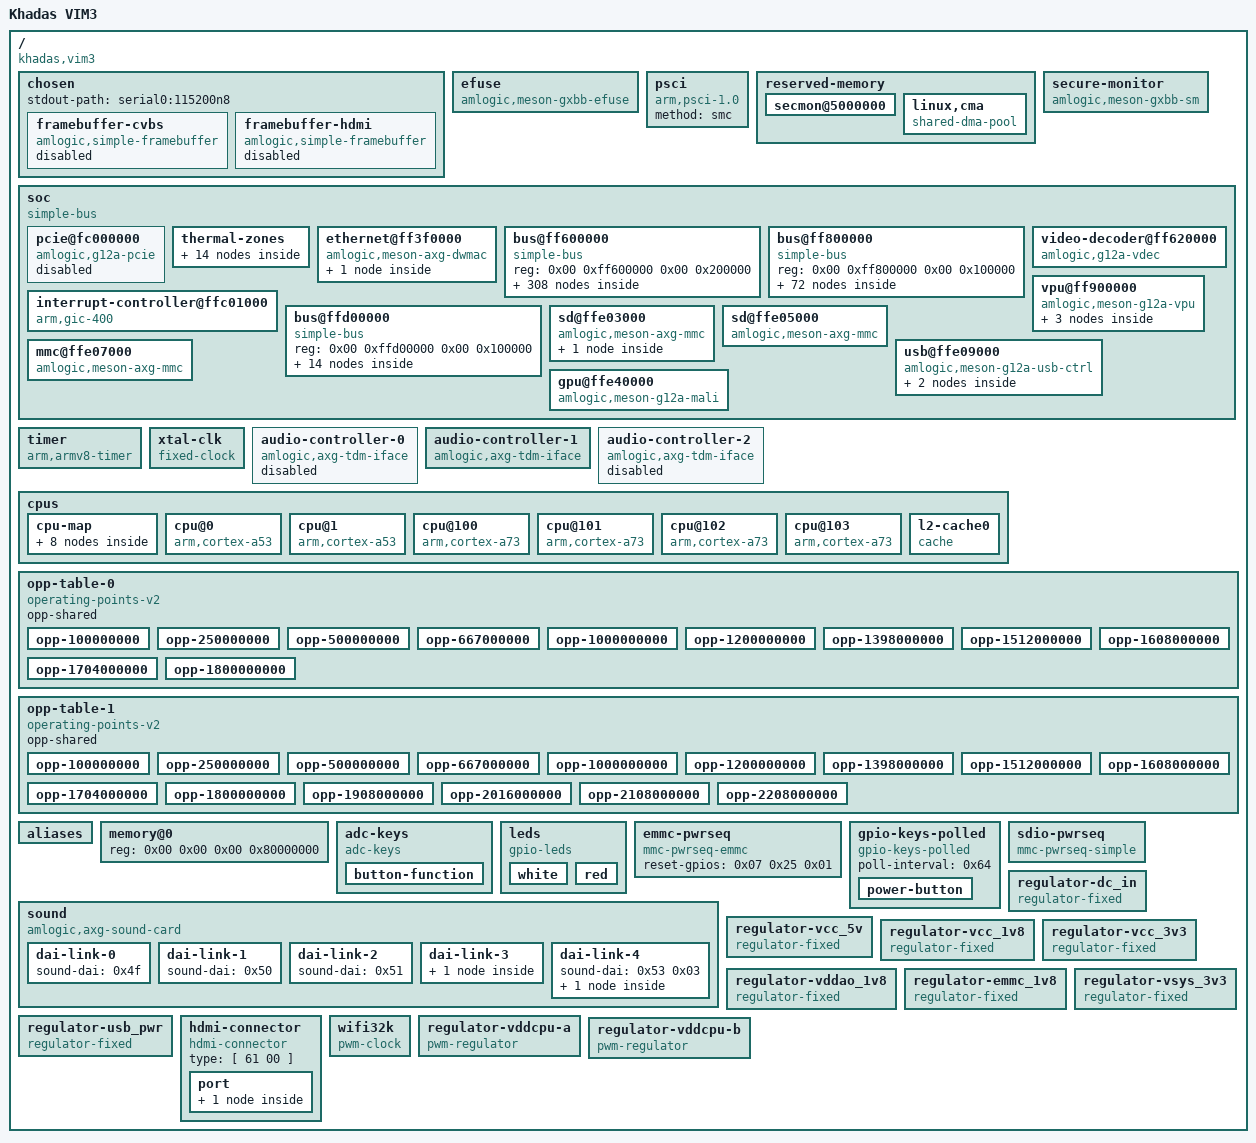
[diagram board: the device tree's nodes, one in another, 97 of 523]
/dts-v1/;

/ {
	interrupt-parent = < 0x01 >;
	#address-cells = < 0x02 >;
	#size-cells = < 0x02 >;
	compatible = "khadas,vim3\0amlogic,a311d\0amlogic,g12b";
	model = "Khadas VIM3";

	chosen {
		#address-cells = < 0x02 >;
		#size-cells = < 0x02 >;
		ranges;
		stdout-path = "serial0:115200n8";

		framebuffer-cvbs {
			compatible = "amlogic,simple-framebuffer\0simple-framebuffer";
			amlogic,pipeline = "vpu-cvbs";
			clocks = < 0x02 0xa8 0x02 0x35 0x02 0x3a >;
			status = "disabled";
			power-domains = < 0x03 0x00 >;
		};

		framebuffer-hdmi {
			compatible = "amlogic,simple-framebuffer\0simple-framebuffer";
			amlogic,pipeline = "vpu-hdmi";
			clocks = < 0x02 0xa8 0x02 0x35 0x02 0x3a >;
			status = "disabled";
			power-domains = < 0x03 0x00 >;
		};
	};

	efuse {
		compatible = "amlogic,meson-gxbb-efuse";
		clocks = < 0x02 0x6a >;
		#address-cells = < 0x01 >;
		#size-cells = < 0x01 >;
		read-only;
		secure-monitor = < 0x04 >;
	};

	psci {
		compatible = "arm,psci-1.0";
		method = "smc";
	};

	reserved-memory {
		#address-cells = < 0x02 >;
		#size-cells = < 0x02 >;
		ranges;

		secmon@5000000 {
			reg = < 0x00 0x5000000 0x00 0x300000 >;
			no-map;
		};

		linux,cma {
			compatible = "shared-dma-pool";
			reusable;
			size = < 0x00 0x10000000 >;
			alignment = < 0x00 0x400000 >;
			linux,cma-default;
		};
	};

	secure-monitor {
		compatible = "amlogic,meson-gxbb-sm";
		phandle = < 0x04 >;
	};

	soc {
		compatible = "simple-bus";
		#address-cells = < 0x02 >;
		#size-cells = < 0x02 >;
		ranges;

		pcie@fc000000 {
			compatible = "amlogic,g12a-pcie\0snps,dw-pcie";
			reg = < 0x00 0xfc000000 0x00 0x400000 0x00 0xff648000 0x00 0x2000 0x00 0xfc400000 0x00 0x200000 >;
			reg-names = "elbi\0cfg\0config";
			interrupts = < 0x00 0xdd 0x04 >;
			#interrupt-cells = < 0x01 >;
			interrupt-map-mask = < 0x00 0x00 0x00 0x00 >;
			interrupt-map = < 0x00 0x00 0x00 0x00 0x01 0x00 0xdf 0x04 >;
			bus-range = < 0x00 0xff >;
			#address-cells = < 0x03 >;
			#size-cells = < 0x02 >;
			device_type = "pci";
			ranges = < 0x81000000 0x00 0x00 0x00 0xfc600000 0x00 0x100000 0x82000000 0x00 0xfc700000 0x00 0xfc700000 0x00 0x1900000 >;
			clocks = < 0x02 0x30 0x02 0x2d 0x02 0xc9 >;
			clock-names = "general\0pclk\0port";
			resets = < 0x05 0x0c 0x05 0x0f >;
			reset-names = "port\0apb";
			num-lanes = < 0x01 >;
			phys = < 0x06 0x02 >;
			phy-names = "pcie";
			status = "disabled";
			reset-gpios = < 0x07 0x39 0x01 >;
		};

		thermal-zones {

			cpu-thermal {
				polling-delay = < 0x3e8 >;
				polling-delay-passive = < 0x64 >;
				thermal-sensors = < 0x08 >;

				trips {

					cpu-passive {
						temperature = < 0x14c08 >;
						hysteresis = < 0x7d0 >;
						type = "passive";
						phandle = < 0x09 >;
					};

					cpu-hot {
						temperature = < 0x17318 >;
						hysteresis = < 0x7d0 >;
						type = "hot";
						phandle = < 0x10 >;
					};

					cpu-critical {
						temperature = < 0x1adb0 >;
						hysteresis = < 0x7d0 >;
						type = "critical";
					};
				};

				cooling-maps {

					map0 {
						trip = < 0x09 >;
						cooling-device = < 0x0a 0xffffffff 0xffffffff 0x0b 0xffffffff 0xffffffff 0x0c 0xffffffff 0xffffffff 0x0d 0xffffffff 0xffffffff 0x0e 0xffffffff 0xffffffff 0x0f 0xffffffff 0xffffffff >;
					};

					map1 {
						trip = < 0x10 >;
						cooling-device = < 0x0a 0xffffffff 0xffffffff 0x0b 0xffffffff 0xffffffff 0x0c 0xffffffff 0xffffffff 0x0d 0xffffffff 0xffffffff 0x0e 0xffffffff 0xffffffff 0x0f 0xffffffff 0xffffffff >;
					};
				};
			};

			ddr-thermal {
				polling-delay = < 0x3e8 >;
				polling-delay-passive = < 0x64 >;
				thermal-sensors = < 0x11 >;

				trips {

					ddr-passive {
						temperature = < 0x14c08 >;
						hysteresis = < 0x7d0 >;
						type = "passive";
						phandle = < 0x12 >;
					};

					ddr-critical {
						temperature = < 0x1adb0 >;
						hysteresis = < 0x7d0 >;
						type = "critical";
					};
				};

				cooling-maps {

					map {
						trip = < 0x12 >;
						cooling-device = < 0x13 0xffffffff 0xffffffff >;
					};
				};
			};
		};

		ethernet@ff3f0000 {
			compatible = "amlogic,meson-axg-dwmac\0snps,dwmac-3.70a\0snps,dwmac";
			reg = < 0x00 0xff3f0000 0x00 0x10000 0x00 0xff634540 0x00 0x08 >;
			interrupts = < 0x00 0x08 0x04 >;
			interrupt-names = "macirq";
			clocks = < 0x02 0x26 0x02 0x02 0x02 0x0d >;
			clock-names = "stmmaceth\0clkin0\0clkin1";
			rx-fifo-depth = < 0x1000 >;
			tx-fifo-depth = < 0x800 >;
			status = "okay";
			power-domains = < 0x03 0x01 >;
			pinctrl-0 = < 0x14 0x15 >;
			pinctrl-names = "default";
			phy-mode = "rgmii";
			phy-handle = < 0x16 >;
			amlogic,tx-delay-ns = < 0x02 >;

			mdio {
				#address-cells = < 0x01 >;
				#size-cells = < 0x00 >;
				compatible = "snps,dwmac-mdio";
				phandle = < 0x22 >;
			};
		};

		bus@ff600000 {
			compatible = "simple-bus";
			reg = < 0x00 0xff600000 0x00 0x200000 >;
			#address-cells = < 0x02 >;
			#size-cells = < 0x02 >;
			ranges = < 0x00 0x00 0x00 0xff600000 0x00 0x200000 >;

			hdmi-tx@0 {
				compatible = "amlogic,meson-g12a-dw-hdmi";
				reg = < 0x00 0x00 0x00 0x10000 >;
				interrupts = < 0x00 0x39 0x01 >;
				resets = < 0x05 0x13 0x05 0x42 0x05 0x4f >;
				reset-names = "hdmitx_apb\0hdmitx\0hdmitx_phy";
				clocks = < 0x02 0xa8 0x02 0x35 0x02 0x3a >;
				clock-names = "isfr\0iahb\0venci";
				#address-cells = < 0x01 >;
				#size-cells = < 0x00 >;
				#sound-dai-cells = < 0x00 >;
				status = "okay";
				pinctrl-0 = < 0x17 0x18 >;
				pinctrl-names = "default";
				hdmi-supply = < 0x19 >;
				phandle = < 0x29 >;

				port@0 {
					reg = < 0x00 >;

					endpoint {
						remote-endpoint = < 0x1a >;
						phandle = < 0x33 >;
					};
				};

				port@1 {
					reg = < 0x01 >;

					endpoint {
						remote-endpoint = < 0x1b >;
						phandle = < 0x54 >;
					};
				};
			};

			bus@30000 {
				compatible = "simple-bus";
				reg = < 0x00 0x30000 0x00 0x2000 >;
				#address-cells = < 0x02 >;
				#size-cells = < 0x02 >;
				ranges = < 0x00 0x00 0x00 0x30000 0x00 0x2000 >;

				rng@218 {
					compatible = "amlogic,meson-rng";
					reg = < 0x00 0x218 0x00 0x04 >;
				};
			};

			audio-controller@32000 {
				compatible = "amlogic,t9015";
				reg = < 0x00 0x32000 0x00 0x14 >;
				#sound-dai-cells = < 0x00 >;
				sound-name-prefix = "ACODEC";
				clocks = < 0x02 0x24 >;
				clock-names = "pclk";
				resets = < 0x05 0x3d >;
				status = "disabled";
			};

			bus@34400 {
				compatible = "simple-bus";
				reg = < 0x00 0x34400 0x00 0x400 >;
				#address-cells = < 0x02 >;
				#size-cells = < 0x02 >;
				ranges = < 0x00 0x00 0x00 0x34400 0x00 0x400 >;

				pinctrl@40 {
					compatible = "amlogic,meson-g12a-periphs-pinctrl";
					#address-cells = < 0x02 >;
					#size-cells = < 0x02 >;
					ranges;
					phandle = < 0x1c >;

					bank@40 {
						reg = < 0x00 0x40 0x00 0x4c 0x00 0xe8 0x00 0x18 0x00 0x120 0x00 0x18 0x00 0x2c0 0x00 0x40 0x00 0x340 0x00 0x1c >;
						reg-names = "gpio\0pull\0pull-enable\0mux\0ds";
						gpio-controller;
						#gpio-cells = < 0x02 >;
						gpio-ranges = < 0x1c 0x00 0x00 0x56 >;
						phandle = < 0x07 >;
					};

					cec_ao_a_h {
						phandle = < 0x28 >;

						mux {
							groups = "cec_ao_a_h";
							function = "cec_ao_a_h";
							bias-disable;
						};
					};

					cec_ao_b_h {
						phandle = < 0x2a >;

						mux {
							groups = "cec_ao_b_h";
							function = "cec_ao_b_h";
							bias-disable;
						};
					};

					emmc {
						phandle = < 0x3f >;

						mux-0 {
							groups = "emmc_nand_d0\0emmc_nand_d1\0emmc_nand_d2\0emmc_nand_d3\0emmc_nand_d4\0emmc_nand_d5\0emmc_nand_d6\0emmc_nand_d7\0emmc_cmd";
							function = "emmc";
							bias-pull-up;
							drive-strength-microamp = < 0xfa0 >;
						};

						mux-1 {
							groups = "emmc_clk";
							function = "emmc";
							bias-disable;
							drive-strength-microamp = < 0xfa0 >;
						};
					};

					emmc-ds {
						phandle = < 0x40 >;

						mux {
							groups = "emmc_nand_ds";
							function = "emmc";
							bias-pull-down;
							drive-strength-microamp = < 0xfa0 >;
						};
					};

					emmc_clk_gate {
						phandle = < 0x41 >;

						mux {
							groups = "BOOT_8";
							function = "gpio_periphs";
							bias-pull-down;
							drive-strength-microamp = < 0xfa0 >;
						};
					};

					hdmitx_ddc {
						phandle = < 0x18 >;

						mux {
							groups = "hdmitx_sda\0hdmitx_sck";
							function = "hdmitx";
							bias-disable;
							drive-strength-microamp = < 0xfa0 >;
						};
					};

					hdmitx_hpd {
						phandle = < 0x17 >;

						mux {
							groups = "hdmitx_hpd_in";
							function = "hdmitx";
							bias-disable;
						};
					};

					i2c0-sda-c {

						mux {
							groups = "i2c0_sda_c";
							function = "i2c0";
							bias-disable;
							drive-strength-microamp = < 0xbb8 >;
						};
					};

					i2c0-sck-c {

						mux {
							groups = "i2c0_sck_c";
							function = "i2c0";
							bias-disable;
							drive-strength-microamp = < 0xbb8 >;
						};
					};

					i2c0-sda-z0 {

						mux {
							groups = "i2c0_sda_z0";
							function = "i2c0";
							bias-disable;
							drive-strength-microamp = < 0xbb8 >;
						};
					};

					i2c0-sck-z1 {

						mux {
							groups = "i2c0_sck_z1";
							function = "i2c0";
							bias-disable;
							drive-strength-microamp = < 0xbb8 >;
						};
					};

					i2c0-sda-z7 {

						mux {
							groups = "i2c0_sda_z7";
							function = "i2c0";
							bias-disable;
							drive-strength-microamp = < 0xbb8 >;
						};
					};

					i2c0-sda-z8 {

						mux {
							groups = "i2c0_sda_z8";
							function = "i2c0";
							bias-disable;
							drive-strength-microamp = < 0xbb8 >;
						};
					};

					i2c1-sda-x {

						mux {
							groups = "i2c1_sda_x";
							function = "i2c1";
							bias-disable;
							drive-strength-microamp = < 0xbb8 >;
						};
					};

					i2c1-sck-x {

						mux {
							groups = "i2c1_sck_x";
							function = "i2c1";
							bias-disable;
							drive-strength-microamp = < 0xbb8 >;
						};
					};

					i2c1-sda-h2 {

						mux {
							groups = "i2c1_sda_h2";
							function = "i2c1";
							bias-disable;
							drive-strength-microamp = < 0xbb8 >;
						};
					};

					i2c1-sck-h3 {

						mux {
							groups = "i2c1_sck_h3";
							function = "i2c1";
							bias-disable;
							drive-strength-microamp = < 0xbb8 >;
						};
					};

					i2c1-sda-h6 {

						mux {
							groups = "i2c1_sda_h6";
							function = "i2c1";
							bias-disable;
							drive-strength-microamp = < 0xbb8 >;
						};
					};

					i2c1-sck-h7 {

						mux {
							groups = "i2c1_sck_h7";
							function = "i2c1";
							bias-disable;
							drive-strength-microamp = < 0xbb8 >;
						};
					};

					i2c2-sda-x {

						mux {
							groups = "i2c2_sda_x";
							function = "i2c2";
							bias-disable;
							drive-strength-microamp = < 0xbb8 >;
						};
					};

					i2c2-sck-x {

						mux {
							groups = "i2c2_sck_x";
							function = "i2c2";
							bias-disable;
							drive-strength-microamp = < 0xbb8 >;
						};
					};

					i2c2-sda-z {

						mux {
							groups = "i2c2_sda_z";
							function = "i2c2";
							bias-disable;
							drive-strength-microamp = < 0xbb8 >;
						};
					};

					i2c2-sck-z {

						mux {
							groups = "i2c2_sck_z";
							function = "i2c2";
							bias-disable;
							drive-strength-microamp = < 0xbb8 >;
						};
					};

					i2c3-sda-h {

						mux {
							groups = "i2c3_sda_h";
							function = "i2c3";
							bias-disable;
							drive-strength-microamp = < 0xbb8 >;
						};
					};

					i2c3-sck-h {

						mux {
							groups = "i2c3_sck_h";
							function = "i2c3";
							bias-disable;
							drive-strength-microamp = < 0xbb8 >;
						};
					};

					i2c3-sda-a {

						mux {
							groups = "i2c3_sda_a";
							function = "i2c3";
							bias-disable;
							drive-strength-microamp = < 0xbb8 >;
						};
					};

					i2c3-sck-a {

						mux {
							groups = "i2c3_sck_a";
							function = "i2c3";
							bias-disable;
							drive-strength-microamp = < 0xbb8 >;
						};
					};

					mclk0-a {

						mux {
							groups = "mclk0_a";
							function = "mclk0";
							bias-disable;
							drive-strength-microamp = < 0xbb8 >;
						};
					};

					mclk1-a {

						mux {
							groups = "mclk1_a";
							function = "mclk1";
							bias-disable;
							drive-strength-microamp = < 0xbb8 >;
						};
					};

					mclk1-x {

						mux {
							groups = "mclk1_x";
							function = "mclk1";
							bias-disable;
							drive-strength-microamp = < 0xbb8 >;
						};
					};

					mclk1-z {

						mux {
							groups = "mclk1_z";
							function = "mclk1";
							bias-disable;
							drive-strength-microamp = < 0xbb8 >;
						};
					};

					pdm-din0-a {

						mux {
							groups = "pdm_din0_a";
							function = "pdm";
							bias-disable;
						};
					};

					pdm-din0-c {

						mux {
							groups = "pdm_din0_c";
							function = "pdm";
							bias-disable;
						};
					};

					pdm-din0-x {

						mux {
							groups = "pdm_din0_x";
							function = "pdm";
							bias-disable;
						};
					};

					pdm-din0-z {

						mux {
							groups = "pdm_din0_z";
							function = "pdm";
							bias-disable;
						};
					};

					pdm-din1-a {

						mux {
							groups = "pdm_din1_a";
							function = "pdm";
							bias-disable;
						};
					};

					pdm-din1-c {

						mux {
							groups = "pdm_din1_c";
							function = "pdm";
							bias-disable;
						};
					};

					pdm-din1-x {

						mux {
							groups = "pdm_din1_x";
							function = "pdm";
							bias-disable;
						};
					};

					pdm-din1-z {

						mux {
							groups = "pdm_din1_z";
							function = "pdm";
							bias-disable;
						};
					};

					pdm-din2-a {

						mux {
							groups = "pdm_din2_a";
							function = "pdm";
							bias-disable;
						};
					};

					pdm-din2-c {

						mux {
							groups = "pdm_din2_c";
							function = "pdm";
							bias-disable;
						};
					};

					pdm-din2-x {

						mux {
							groups = "pdm_din2_x";
							function = "pdm";
							bias-disable;
						};
					};

					pdm-din2-z {

						mux {
							groups = "pdm_din2_z";
							function = "pdm";
							bias-disable;
						};
					};

					pdm-din3-a {

						mux {
							groups = "pdm_din3_a";
							function = "pdm";
							bias-disable;
						};
					};

					pdm-din3-c {

						mux {
							groups = "pdm_din3_c";
							function = "pdm";
							bias-disable;
						};
					};

					pdm-din3-x {

						mux {
							groups = "pdm_din3_x";
							function = "pdm";
							bias-disable;
						};
					};

					pdm-din3-z {

						mux {
							groups = "pdm_din3_z";
							function = "pdm";
							bias-disable;
						};
					};

					pdm-dclk-a {

						mux {
							groups = "pdm_dclk_a";
							function = "pdm";
							bias-disable;
							drive-strength-microamp = < 0x1f4 >;
						};
					};

					pdm-dclk-c {

						mux {
							groups = "pdm_dclk_c";
							function = "pdm";
							bias-disable;
							drive-strength-microamp = < 0x1f4 >;
						};
					};

					pdm-dclk-x {

						mux {
							groups = "pdm_dclk_x";
							function = "pdm";
							bias-disable;
							drive-strength-microamp = < 0x1f4 >;
						};
					};

					pdm-dclk-z {

						mux {
							groups = "pdm_dclk_z";
							function = "pdm";
							bias-disable;
							drive-strength-microamp = < 0x1f4 >;
						};
					};

					pwm-a {

						mux {
							groups = "pwm_a";
							function = "pwm_a";
							bias-disable;
						};
					};

					pwm-b-x7 {

						mux {
							groups = "pwm_b_x7";
							function = "pwm_b";
							bias-disable;
						};
					};

					pwm-b-x19 {

						mux {
							groups = "pwm_b_x19";
							function = "pwm_b";
							bias-disable;
						};
					};

					pwm-c-c {

						mux {
							groups = "pwm_c_c";
							function = "pwm_c";
							bias-disable;
						};
					};

					pwm-c-x5 {

						mux {
							groups = "pwm_c_x5";
							function = "pwm_c";
							bias-disable;
						};
					};

					pwm-c-x8 {

						mux {
							groups = "pwm_c_x8";
							function = "pwm_c";
							bias-disable;
						};
					};

					pwm-d-x3 {

						mux {
							groups = "pwm_d_x3";
							function = "pwm_d";
							bias-disable;
						};
					};

					pwm-d-x6 {

						mux {
							groups = "pwm_d_x6";
							function = "pwm_d";
							bias-disable;
						};
					};

					pwm-e {
						phandle = < 0x34 >;

						mux {
							groups = "pwm_e";
							function = "pwm_e";
							bias-disable;
						};
					};

					pwm-f-x {

						mux {
							groups = "pwm_f_x";
							function = "pwm_f";
							bias-disable;
						};
					};

					pwm-f-h {

						mux {
							groups = "pwm_f_h";
							function = "pwm_f";
							bias-disable;
						};
					};

					sdcard_c {
						phandle = < 0x3d >;

						mux-0 {
							groups = "sdcard_d0_c\0sdcard_d1_c\0sdcard_d2_c\0sdcard_d3_c\0sdcard_cmd_c";
							function = "sdcard";
							bias-pull-up;
							drive-strength-microamp = < 0xfa0 >;
						};

						mux-1 {
							groups = "sdcard_clk_c";
							function = "sdcard";
							bias-disable;
							drive-strength-microamp = < 0xfa0 >;
						};
					};

					sdcard_clk_gate_c {
						phandle = < 0x3e >;

						mux {
							groups = "GPIOC_4";
							function = "gpio_periphs";
							bias-pull-down;
							drive-strength-microamp = < 0xfa0 >;
						};
					};

					sdcard_z {

						mux-0 {
							groups = "sdcard_d0_z\0sdcard_d1_z\0sdcard_d2_z\0sdcard_d3_z\0sdcard_cmd_z";
							function = "sdcard";
							bias-pull-up;
							drive-strength-microamp = < 0xfa0 >;
						};

						mux-1 {
							groups = "sdcard_clk_z";
							function = "sdcard";
							bias-disable;
							drive-strength-microamp = < 0xfa0 >;
						};
					};

					sdcard_clk_gate_z {

						mux {
							groups = "GPIOZ_6";
							function = "gpio_periphs";
							bias-pull-down;
							drive-strength-microamp = < 0xfa0 >;
						};
					};

					sdio {
						phandle = < 0x39 >;

						mux {
							groups = "sdio_d0\0sdio_d1\0sdio_d2\0sdio_d3\0sdio_clk\0sdio_cmd";
							function = "sdio";
							bias-disable;
							drive-strength-microamp = < 0xfa0 >;
						};
					};

					sdio_clk_gate {
						phandle = < 0x3a >;

						mux {
							groups = "GPIOX_4";
							function = "gpio_periphs";
							bias-pull-down;
							drive-strength-microamp = < 0xfa0 >;
						};
					};

					spdif-in-a10 {

						mux {
							groups = "spdif_in_a10";
							function = "spdif_in";
							bias-disable;
						};
					};

					spdif-in-a12 {

						mux {
							groups = "spdif_in_a12";
							function = "spdif_in";
							bias-disable;
						};
					};

					spdif-in-h {

						mux {
							groups = "spdif_in_h";
							function = "spdif_in";
							bias-disable;
						};
					};

					spdif-out-h {

						mux {
							groups = "spdif_out_h";
							function = "spdif_out";
							drive-strength-microamp = < 0x1f4 >;
							bias-disable;
						};
					};

					spdif-out-a11 {

						mux {
							groups = "spdif_out_a11";
							function = "spdif_out";
							drive-strength-microamp = < 0x1f4 >;
							bias-disable;
						};
					};

					spdif-out-a13 {

						mux {
							groups = "spdif_out_a13";
							function = "spdif_out";
							drive-strength-microamp = < 0x1f4 >;
							bias-disable;
						};
					};

					tdm-a-din0 {

						mux {
							groups = "tdm_a_din0";
							function = "tdm_a";
							bias-disable;
						};
					};

					tdm-a-din1 {

						mux {
							groups = "tdm_a_din1";
							function = "tdm_a";
							bias-disable;
						};
					};

					tdm-a-dout0 {

						mux {
							groups = "tdm_a_dout0";
							function = "tdm_a";
							bias-disable;
							drive-strength-microamp = < 0xbb8 >;
						};
					};

					tdm-a-dout1 {

						mux {
							groups = "tdm_a_dout1";
							function = "tdm_a";
							bias-disable;
							drive-strength-microamp = < 0xbb8 >;
						};
					};

					tdm-a-fs {

						mux {
							groups = "tdm_a_fs";
							function = "tdm_a";
							bias-disable;
							drive-strength-microamp = < 0xbb8 >;
						};
					};

					tdm-a-sclk {

						mux {
							groups = "tdm_a_sclk";
							function = "tdm_a";
							bias-disable;
							drive-strength-microamp = < 0xbb8 >;
						};
					};

					tdm-a-slv-fs {

						mux {
							groups = "tdm_a_slv_fs";
							function = "tdm_a";
							bias-disable;
						};
					};

					tdm-a-slv-sclk {

						mux {
							groups = "tdm_a_slv_sclk";
							function = "tdm_a";
							bias-disable;
						};
					};

					tdm-b-din0 {

						mux {
							groups = "tdm_b_din0";
							function = "tdm_b";
							bias-disable;
						};
					};

					tdm-b-din1 {

						mux {
							groups = "tdm_b_din1";
							function = "tdm_b";
							bias-disable;
						};
					};

					tdm-b-din2 {

						mux {
							groups = "tdm_b_din2";
							function = "tdm_b";
							bias-disable;
						};
					};

					tdm-b-din3-a {

						mux {
							groups = "tdm_b_din3_a";
							function = "tdm_b";
							bias-disable;
						};
					};

					tdm-b-din3-h {

						mux {
							groups = "tdm_b_din3_h";
							function = "tdm_b";
							bias-disable;
						};
					};

					tdm-b-dout0 {

						mux {
							groups = "tdm_b_dout0";
							function = "tdm_b";
							bias-disable;
							drive-strength-microamp = < 0xbb8 >;
						};
					};

					tdm-b-dout1 {

						mux {
							groups = "tdm_b_dout1";
							function = "tdm_b";
							bias-disable;
							drive-strength-microamp = < 0xbb8 >;
						};
					};

					tdm-b-dout2 {

						mux {
							groups = "tdm_b_dout2";
							function = "tdm_b";
							bias-disable;
							drive-strength-microamp = < 0xbb8 >;
						};
					};

					tdm-b-dout3-a {

						mux {
							groups = "tdm_b_dout3_a";
							function = "tdm_b";
							bias-disable;
							drive-strength-microamp = < 0xbb8 >;
						};
					};

					tdm-b-dout3-h {

						mux {
							groups = "tdm_b_dout3_h";
							function = "tdm_b";
							bias-disable;
							drive-strength-microamp = < 0xbb8 >;
						};
					};

					tdm-b-fs {

						mux {
							groups = "tdm_b_fs";
							function = "tdm_b";
							bias-disable;
							drive-strength-microamp = < 0xbb8 >;
						};
					};

					tdm-b-sclk {

						mux {
							groups = "tdm_b_sclk";
							function = "tdm_b";
							bias-disable;
							drive-strength-microamp = < 0xbb8 >;
						};
					};

					tdm-b-slv-fs {

						mux {
							groups = "tdm_b_slv_fs";
							function = "tdm_b";
							bias-disable;
						};
					};

					tdm-b-slv-sclk {

						mux {
							groups = "tdm_b_slv_sclk";
							function = "tdm_b";
							bias-disable;
						};
					};

					tdm-c-din0-a {

						mux {
							groups = "tdm_c_din0_a";
							function = "tdm_c";
							bias-disable;
						};
					};

					tdm-c-din0-z {

						mux {
							groups = "tdm_c_din0_z";
							function = "tdm_c";
							bias-disable;
						};
					};

					tdm-c-din1-a {

						mux {
							groups = "tdm_c_din1_a";
							function = "tdm_c";
							bias-disable;
						};
					};

					tdm-c-din1-z {

						mux {
							groups = "tdm_c_din1_z";
							function = "tdm_c";
							bias-disable;
						};
					};

					tdm-c-din2-a {

						mux {
							groups = "tdm_c_din2_a";
							function = "tdm_c";
							bias-disable;
						};
					};

					eth-leds {

						mux {
							groups = "eth_link_led\0eth_act_led";
							function = "eth";
							bias-disable;
						};
					};

					eth {
						phandle = < 0x14 >;

						mux {
							groups = "eth_mdio\0eth_mdc\0eth_rgmii_rx_clk\0eth_rx_dv\0eth_rxd0\0eth_rxd1\0eth_txen\0eth_txd0\0eth_txd1";
							function = "eth";
							drive-strength-microamp = < 0xfa0 >;
							bias-disable;
						};
					};

					eth-rgmii {
						phandle = < 0x15 >;

						mux {
							groups = "eth_rxd2_rgmii\0eth_rxd3_rgmii\0eth_rgmii_tx_clk\0eth_txd2_rgmii\0eth_txd3_rgmii";
							function = "eth";
							drive-strength-microamp = < 0xfa0 >;
							bias-disable;
						};
					};

					tdm-c-din2-z {

						mux {
							groups = "tdm_c_din2_z";
							function = "tdm_c";
							bias-disable;
						};
					};

					tdm-c-din3-a {

						mux {
							groups = "tdm_c_din3_a";
							function = "tdm_c";
							bias-disable;
						};
					};

					tdm-c-din3-z {

						mux {
							groups = "tdm_c_din3_z";
							function = "tdm_c";
							bias-disable;
						};
					};

					tdm-c-dout0-a {

						mux {
							groups = "tdm_c_dout0_a";
							function = "tdm_c";
							bias-disable;
							drive-strength-microamp = < 0xbb8 >;
						};
					};

					tdm-c-dout0-z {

						mux {
							groups = "tdm_c_dout0_z";
							function = "tdm_c";
							bias-disable;
							drive-strength-microamp = < 0xbb8 >;
						};
					};

					tdm-c-dout1-a {

						mux {
							groups = "tdm_c_dout1_a";
							function = "tdm_c";
							bias-disable;
							drive-strength-microamp = < 0xbb8 >;
						};
					};

					tdm-c-dout1-z {

						mux {
							groups = "tdm_c_dout1_z";
							function = "tdm_c";
							bias-disable;
							drive-strength-microamp = < 0xbb8 >;
						};
					};

					tdm-c-dout2-a {

						mux {
							groups = "tdm_c_dout2_a";
							function = "tdm_c";
							bias-disable;
							drive-strength-microamp = < 0xbb8 >;
						};
					};

					tdm-c-dout2-z {

						mux {
							groups = "tdm_c_dout2_z";
							function = "tdm_c";
							bias-disable;
							drive-strength-microamp = < 0xbb8 >;
						};
					};

					tdm-c-dout3-a {

						mux {
							groups = "tdm_c_dout3_a";
							function = "tdm_c";
							bias-disable;
							drive-strength-microamp = < 0xbb8 >;
						};
					};

					tdm-c-dout3-z {

						mux {
							groups = "tdm_c_dout3_z";
							function = "tdm_c";
							bias-disable;
							drive-strength-microamp = < 0xbb8 >;
						};
					};

					tdm-c-fs-a {

						mux {
							groups = "tdm_c_fs_a";
							function = "tdm_c";
							bias-disable;
							drive-strength-microamp = < 0xbb8 >;
						};
					};

					tdm-c-fs-z {

						mux {
							groups = "tdm_c_fs_z";
							function = "tdm_c";
							bias-disable;
							drive-strength-microamp = < 0xbb8 >;
						};
					};

					tdm-c-sclk-a {

						mux {
							groups = "tdm_c_sclk_a";
							function = "tdm_c";
							bias-disable;
							drive-strength-microamp = < 0xbb8 >;
						};
					};

					tdm-c-sclk-z {

						mux {
							groups = "tdm_c_sclk_z";
							function = "tdm_c";
							bias-disable;
							drive-strength-microamp = < 0xbb8 >;
						};
					};

					tdm-c-slv-fs-a {

						mux {
							groups = "tdm_c_slv_fs_a";
							function = "tdm_c";
							bias-disable;
						};
					};

					tdm-c-slv-fs-z {

						mux {
							groups = "tdm_c_slv_fs_z";
							function = "tdm_c";
							bias-disable;
						};
					};

					tdm-c-slv-sclk-a {

						mux {
							groups = "tdm_c_slv_sclk_a";
							function = "tdm_c";
							bias-disable;
						};
					};

					tdm-c-slv-sclk-z {

						mux {
							groups = "tdm_c_slv_sclk_z";
							function = "tdm_c";
							bias-disable;
						};
					};

					uart-a {
						phandle = < 0x36 >;

						mux {
							groups = "uart_a_tx\0uart_a_rx";
							function = "uart_a";
							bias-disable;
						};
					};

					uart-a-cts-rts {
						phandle = < 0x37 >;

						mux {
							groups = "uart_a_cts\0uart_a_rts";
							function = "uart_a";
							bias-disable;
						};
					};

					uart-b {

						mux {
							groups = "uart_b_tx\0uart_b_rx";
							function = "uart_b";
							bias-disable;
						};
					};

					uart-c {

						mux {
							groups = "uart_c_tx\0uart_c_rx";
							function = "uart_c";
							bias-disable;
						};
					};

					uart-c-cts-rts {

						mux {
							groups = "uart_c_cts\0uart_c_rts";
							function = "uart_c";
							bias-disable;
						};
					};
				};
			};

			temperature-sensor@34800 {
				compatible = "amlogic,g12a-cpu-thermal\0amlogic,g12a-thermal";
				reg = < 0x00 0x34800 0x00 0x50 >;
				interrupts = < 0x00 0x23 0x01 >;
				clocks = < 0x02 0xd4 >;
				#thermal-sensor-cells = < 0x00 >;
				amlogic,ao-secure = < 0x1d >;
				phandle = < 0x08 >;
			};

			temperature-sensor@34c00 {
				compatible = "amlogic,g12a-ddr-thermal\0amlogic,g12a-thermal";
				reg = < 0x00 0x34c00 0x00 0x50 >;
				interrupts = < 0x00 0x24 0x01 >;
				clocks = < 0x02 0xd4 >;
				#thermal-sensor-cells = < 0x00 >;
				amlogic,ao-secure = < 0x1d >;
				phandle = < 0x11 >;
			};

			phy@36000 {
				compatible = "amlogic,g12a-usb2-phy";
				reg = < 0x00 0x36000 0x00 0x2000 >;
				clocks = < 0x1e >;
				clock-names = "xtal";
				resets = < 0x05 0x30 >;
				reset-names = "phy";
				#phy-cells = < 0x00 >;
				phy-supply = < 0x1f >;
				phandle = < 0x44 >;
			};

			bus@38000 {
				compatible = "simple-bus";
				reg = < 0x00 0x38000 0x00 0x400 >;
				#address-cells = < 0x02 >;
				#size-cells = < 0x02 >;
				ranges = < 0x00 0x00 0x00 0x38000 0x00 0x400 >;

				video-lut@48 {
					compatible = "amlogic,canvas";
					reg = < 0x00 0x48 0x00 0x14 >;
					phandle = < 0x32 >;
				};
			};

			phy@3a000 {
				compatible = "amlogic,g12a-usb2-phy";
				reg = < 0x00 0x3a000 0x00 0x2000 >;
				clocks = < 0x1e >;
				clock-names = "xtal";
				resets = < 0x05 0x31 >;
				reset-names = "phy";
				#phy-cells = < 0x00 >;
				phy-supply = < 0x20 >;
				phandle = < 0x45 >;
			};

			bus@3c000 {
				compatible = "simple-bus";
				reg = < 0x00 0x3c000 0x00 0x1400 >;
				#address-cells = < 0x02 >;
				#size-cells = < 0x02 >;
				ranges = < 0x00 0x00 0x00 0x3c000 0x00 0x1400 >;

				system-controller@0 {
					compatible = "amlogic,meson-gx-hhi-sysctrl\0simple-mfd\0syscon";
					reg = < 0x00 0x00 0x00 0x400 >;

					clock-controller {
						compatible = "amlogic,g12b-clkc";
						#clock-cells = < 0x01 >;
						clocks = < 0x1e >;
						clock-names = "xtal";
						phandle = < 0x02 >;
					};

					power-controller {
						compatible = "amlogic,meson-g12a-pwrc";
						#power-domain-cells = < 0x01 >;
						amlogic,ao-sysctrl = < 0x21 >;
						resets = < 0x05 0x05 0x05 0x0a 0x05 0x0d 0x05 0x25 0x05 0x85 0x05 0x86 0x05 0x87 0x05 0x89 0x05 0x8c 0x05 0x8d 0x05 0xe7 >;
						reset-names = "viu\0venc\0vcbus\0bt656\0rdma\0venci\0vencp\0vdac\0vdi6\0vencl\0vid_lock";
						clocks = < 0x02 0x74 0x02 0x7c >;
						clock-names = "vpu\0vapb";
						assigned-clocks = < 0x02 0x6e 0x02 0x70 0x02 0x74 0x02 0x75 0x02 0x77 0x02 0x7b >;
						assigned-clock-parents = < 0x02 0x03 0x00 0x02 0x70 0x02 0x04 0x00 0x02 0x77 >;
						assigned-clock-rates = < 0x00 0x27bc86aa 0x00 0x00 0xee6b280 0x00 >;
						phandle = < 0x03 >;
					};
				};
			};

			phy@46000 {
				compatible = "amlogic,g12a-usb3-pcie-phy";
				reg = < 0x00 0x46000 0x00 0x2000 >;
				clocks = < 0x02 0xc9 >;
				clock-names = "ref_clk";
				resets = < 0x05 0x0e >;
				reset-names = "phy";
				assigned-clocks = < 0x02 0xc9 >;
				assigned-clock-rates = < 0x5f5e100 >;
				#phy-cells = < 0x01 >;
				phy-supply = < 0x20 >;
				phandle = < 0x06 >;
			};

			mdio-multiplexer@4c000 {
				compatible = "amlogic,g12a-mdio-mux";
				reg = < 0x00 0x4c000 0x00 0xa4 >;
				clocks = < 0x02 0x13 0x1e 0x02 0xb1 >;
				clock-names = "pclk\0clkin0\0clkin1";
				mdio-parent-bus = < 0x22 >;
				#address-cells = < 0x01 >;
				#size-cells = < 0x00 >;

				mdio@0 {
					reg = < 0x00 >;
					#address-cells = < 0x01 >;
					#size-cells = < 0x00 >;

					ethernet-phy@0 {
						reg = < 0x00 >;
						max-speed = < 0x3e8 >;
						interrupt-parent = < 0x23 >;
						interrupts = < 0x1a 0x08 >;
						phandle = < 0x16 >;
					};
				};

				mdio@1 {
					reg = < 0x01 >;
					#address-cells = < 0x01 >;
					#size-cells = < 0x00 >;

					ethernet_phy@8 {
						compatible = "ethernet-phy-id0180.3301\0ethernet-phy-ieee802.3-c22";
						interrupts = < 0x00 0x09 0x04 >;
						reg = < 0x08 >;
						max-speed = < 0x64 >;
					};
				};
			};

			audio-controller@40000 {
				compatible = "amlogic,g12a-pdm\0amlogic,axg-pdm";
				reg = < 0x00 0x40000 0x00 0x34 >;
				#sound-dai-cells = < 0x00 >;
				sound-name-prefix = "PDM";
				clocks = < 0x24 0x1e 0x24 0x39 0x24 0x3a >;
				clock-names = "pclk\0dclk\0sysclk";
				status = "disabled";
			};

			bus@42000 {
				compatible = "simple-bus";
				reg = < 0x00 0x42000 0x00 0x2000 >;
				#address-cells = < 0x02 >;
				#size-cells = < 0x02 >;
				ranges = < 0x00 0x00 0x00 0x42000 0x00 0x2000 >;

				clock-controller@0 {
					status = "okay";
					compatible = "amlogic,g12a-audio-clkc";
					reg = < 0x00 0x00 0x00 0xb4 >;
					#clock-cells = < 0x01 >;
					#reset-cells = < 0x01 >;
					clocks = < 0x02 0x25 0x02 0x0b 0x02 0x0c 0x02 0x0d 0x02 0x0e 0x02 0x4a 0x02 0x03 0x02 0x04 0x02 0x07 >;
					clock-names = "pclk\0mst_in0\0mst_in1\0mst_in2\0mst_in3\0mst_in4\0mst_in5\0mst_in6\0mst_in7";
					resets = < 0x05 0x41 >;
					phandle = < 0x24 >;
				};

				audio-controller@100 {
					compatible = "amlogic,g12a-toddr\0amlogic,axg-toddr";
					reg = < 0x00 0x100 0x00 0x2c >;
					#sound-dai-cells = < 0x00 >;
					sound-name-prefix = "TODDR_A";
					interrupts = < 0x00 0x94 0x01 >;
					clocks = < 0x24 0x29 >;
					resets = < 0x25 0x00 0x24 0x06 >;
					reset-names = "arb\0rst";
					status = "disabled";
				};

				audio-controller@140 {
					compatible = "amlogic,g12a-toddr\0amlogic,axg-toddr";
					reg = < 0x00 0x140 0x00 0x2c >;
					#sound-dai-cells = < 0x00 >;
					sound-name-prefix = "TODDR_B";
					interrupts = < 0x00 0x95 0x01 >;
					clocks = < 0x24 0x2a >;
					resets = < 0x25 0x01 0x24 0x07 >;
					reset-names = "arb\0rst";
					status = "disabled";
				};

				audio-controller@180 {
					compatible = "amlogic,g12a-toddr\0amlogic,axg-toddr";
					reg = < 0x00 0x180 0x00 0x2c >;
					#sound-dai-cells = < 0x00 >;
					sound-name-prefix = "TODDR_C";
					interrupts = < 0x00 0x96 0x01 >;
					clocks = < 0x24 0x2b >;
					resets = < 0x25 0x02 0x24 0x08 >;
					reset-names = "arb\0rst";
					status = "disabled";
				};

				audio-controller@1c0 {
					compatible = "amlogic,g12a-frddr\0amlogic,axg-frddr";
					reg = < 0x00 0x1c0 0x00 0x2c >;
					#sound-dai-cells = < 0x00 >;
					sound-name-prefix = "FRDDR_A";
					interrupts = < 0x00 0x98 0x01 >;
					clocks = < 0x24 0x26 >;
					resets = < 0x25 0x03 0x24 0x09 >;
					reset-names = "arb\0rst";
					status = "okay";
					phandle = < 0x4f >;
				};

				audio-controller@200 {
					compatible = "amlogic,g12a-frddr\0amlogic,axg-frddr";
					reg = < 0x00 0x200 0x00 0x2c >;
					#sound-dai-cells = < 0x00 >;
					sound-name-prefix = "FRDDR_B";
					interrupts = < 0x00 0x99 0x01 >;
					clocks = < 0x24 0x27 >;
					resets = < 0x25 0x04 0x24 0x0a >;
					reset-names = "arb\0rst";
					status = "okay";
					phandle = < 0x50 >;
				};

				audio-controller@240 {
					compatible = "amlogic,g12a-frddr\0amlogic,axg-frddr";
					reg = < 0x00 0x240 0x00 0x2c >;
					#sound-dai-cells = < 0x00 >;
					sound-name-prefix = "FRDDR_C";
					interrupts = < 0x00 0x9a 0x01 >;
					clocks = < 0x24 0x28 >;
					resets = < 0x25 0x05 0x24 0x0b >;
					reset-names = "arb\0rst";
					status = "okay";
					phandle = < 0x51 >;
				};

				reset-controller@280 {
					status = "okay";
					compatible = "amlogic,meson-axg-audio-arb";
					reg = < 0x00 0x280 0x00 0x04 >;
					#reset-cells = < 0x01 >;
					clocks = < 0x24 0x1d >;
					phandle = < 0x25 >;
				};

				audio-controller@300 {
					compatible = "amlogic,g12a-tdmin\0amlogic,axg-tdmin";
					reg = < 0x00 0x300 0x00 0x40 >;
					sound-name-prefix = "TDMIN_A";
					resets = < 0x24 0x01 >;
					clocks = < 0x24 0x1f 0x24 0x7b 0x24 0x74 0x24 0x82 0x24 0x82 >;
					clock-names = "pclk\0sclk\0sclk_sel\0lrclk\0lrclk_sel";
					status = "disabled";
				};

				audio-controller@340 {
					compatible = "amlogic,g12a-tdmin\0amlogic,axg-tdmin";
					reg = < 0x00 0x340 0x00 0x40 >;
					sound-name-prefix = "TDMIN_B";
					resets = < 0x24 0x02 >;
					clocks = < 0x24 0x20 0x24 0x7c 0x24 0x75 0x24 0x83 0x24 0x83 >;
					clock-names = "pclk\0sclk\0sclk_sel\0lrclk\0lrclk_sel";
					status = "disabled";
				};

				audio-controller@380 {
					compatible = "amlogic,g12a-tdmin\0amlogic,axg-tdmin";
					reg = < 0x00 0x380 0x00 0x40 >;
					sound-name-prefix = "TDMIN_C";
					resets = < 0x24 0x03 >;
					clocks = < 0x24 0x21 0x24 0x7d 0x24 0x76 0x24 0x84 0x24 0x84 >;
					clock-names = "pclk\0sclk\0sclk_sel\0lrclk\0lrclk_sel";
					status = "disabled";
				};

				audio-controller@3c0 {
					compatible = "amlogic,g12a-tdmin\0amlogic,axg-tdmin";
					reg = < 0x00 0x3c0 0x00 0x40 >;
					sound-name-prefix = "TDMIN_LB";
					resets = < 0x24 0x04 >;
					clocks = < 0x24 0x22 0x24 0x7e 0x24 0x77 0x24 0x85 0x24 0x85 >;
					clock-names = "pclk\0sclk\0sclk_sel\0lrclk\0lrclk_sel";
					status = "disabled";
				};

				audio-controller@400 {
					compatible = "amlogic,g12a-spdifin\0amlogic,axg-spdifin";
					reg = < 0x00 0x400 0x00 0x30 >;
					#sound-dai-cells = < 0x00 >;
					sound-name-prefix = "SPDIFIN";
					interrupts = < 0x00 0x97 0x01 >;
					clocks = < 0x24 0x2d 0x24 0x38 >;
					clock-names = "pclk\0refclk";
					resets = < 0x24 0x11 >;
					status = "disabled";
				};

				audio-controller@480 {
					compatible = "amlogic,g12a-spdifout\0amlogic,axg-spdifout";
					reg = < 0x00 0x480 0x00 0x50 >;
					#sound-dai-cells = < 0x00 >;
					sound-name-prefix = "SPDIFOUT";
					clocks = < 0x24 0x2e 0x24 0x37 >;
					clock-names = "pclk\0mclk";
					resets = < 0x24 0x0f >;
					status = "disabled";
				};

				audio-controller@500 {
					compatible = "amlogic,g12a-tdmout";
					reg = < 0x00 0x500 0x00 0x40 >;
					sound-name-prefix = "TDMOUT_A";
					resets = < 0x24 0x0c >;
					clocks = < 0x24 0x23 0x24 0x7f 0x24 0x78 0x24 0x86 0x24 0x86 >;
					clock-names = "pclk\0sclk\0sclk_sel\0lrclk\0lrclk_sel";
					status = "disabled";
				};

				audio-controller@540 {
					compatible = "amlogic,g12a-tdmout";
					reg = < 0x00 0x540 0x00 0x40 >;
					sound-name-prefix = "TDMOUT_B";
					resets = < 0x24 0x0d >;
					clocks = < 0x24 0x24 0x24 0x80 0x24 0x79 0x24 0x87 0x24 0x87 >;
					clock-names = "pclk\0sclk\0sclk_sel\0lrclk\0lrclk_sel";
					status = "okay";
					phandle = < 0x4e >;
				};

				audio-controller@580 {
					compatible = "amlogic,g12a-tdmout";
					reg = < 0x00 0x580 0x00 0x40 >;
					sound-name-prefix = "TDMOUT_C";
					resets = < 0x24 0x0e >;
					clocks = < 0x24 0x25 0x24 0x81 0x24 0x7a 0x24 0x88 0x24 0x88 >;
					clock-names = "pclk\0sclk\0sclk_sel\0lrclk\0lrclk_sel";
					status = "disabled";
				};

				audio-controller@680 {
					compatible = "amlogic,g12a-spdifout\0amlogic,axg-spdifout";
					reg = < 0x00 0x680 0x00 0x50 >;
					#sound-dai-cells = < 0x00 >;
					sound-name-prefix = "SPDIFOUT_B";
					clocks = < 0x24 0x97 0x24 0x98 >;
					clock-names = "pclk\0mclk";
					resets = < 0x24 0x10 >;
					status = "disabled";
				};

				audio-controller@740 {
					compatible = "amlogic,g12a-toacodec";
					reg = < 0x00 0x740 0x00 0x04 >;
					#sound-dai-cells = < 0x01 >;
					sound-name-prefix = "TOACODEC";
					resets = < 0x24 0x17 >;
					status = "disabled";
				};

				audio-controller@744 {
					compatible = "amlogic,g12a-tohdmitx";
					reg = < 0x00 0x744 0x00 0x04 >;
					#sound-dai-cells = < 0x01 >;
					sound-name-prefix = "TOHDMITX";
					resets = < 0x24 0x18 >;
					status = "okay";
					phandle = < 0x53 >;
				};
			};
		};

		bus@ff800000 {
			compatible = "simple-bus";
			reg = < 0x00 0xff800000 0x00 0x100000 >;
			#address-cells = < 0x02 >;
			#size-cells = < 0x02 >;
			ranges = < 0x00 0x00 0x00 0xff800000 0x00 0x100000 >;

			sys-ctrl@0 {
				compatible = "amlogic,meson-gx-ao-sysctrl\0simple-mfd\0syscon";
				reg = < 0x00 0x00 0x00 0x100 >;
				#address-cells = < 0x02 >;
				#size-cells = < 0x02 >;
				ranges = < 0x00 0x00 0x00 0x00 0x00 0x100 >;
				phandle = < 0x21 >;

				clock-controller {
					compatible = "amlogic,meson-g12a-aoclkc";
					#clock-cells = < 0x01 >;
					#reset-cells = < 0x01 >;
					clocks = < 0x1e 0x02 0x0a >;
					clock-names = "xtal\0mpeg-clk";
					phandle = < 0x27 >;
				};

				pinctrl@14 {
					compatible = "amlogic,meson-g12a-aobus-pinctrl";
					#address-cells = < 0x02 >;
					#size-cells = < 0x02 >;
					ranges;
					phandle = < 0x26 >;

					bank@14 {
						reg = < 0x00 0x14 0x00 0x08 0x00 0x1c 0x00 0x08 0x00 0x24 0x00 0x14 >;
						reg-names = "mux\0ds\0gpio";
						gpio-controller;
						#gpio-cells = < 0x02 >;
						gpio-ranges = < 0x26 0x00 0x00 0x0f >;
						phandle = < 0x4c >;
					};

					i2c_ao_sck_pins {
						phandle = < 0x2d >;

						mux {
							groups = "i2c_ao_sck";
							function = "i2c_ao";
							bias-disable;
							drive-strength-microamp = < 0xbb8 >;
						};
					};

					i2c_ao_sda {
						phandle = < 0x2e >;

						mux {
							groups = "i2c_ao_sda";
							function = "i2c_ao";
							bias-disable;
							drive-strength-microamp = < 0xbb8 >;
						};
					};

					i2c_ao_sck_e {

						mux {
							groups = "i2c_ao_sck_e";
							function = "i2c_ao";
							bias-disable;
							drive-strength-microamp = < 0xbb8 >;
						};
					};

					i2c_ao_sda_e {

						mux {
							groups = "i2c_ao_sda_e";
							function = "i2c_ao";
							bias-disable;
							drive-strength-microamp = < 0xbb8 >;
						};
					};

					mclk0-ao {

						mux {
							groups = "mclk0_ao";
							function = "mclk0_ao";
							bias-disable;
							drive-strength-microamp = < 0xbb8 >;
						};
					};

					tdm-ao-b-din0 {

						mux {
							groups = "tdm_ao_b_din0";
							function = "tdm_ao_b";
							bias-disable;
						};
					};

					spdif-ao-out {

						mux {
							groups = "spdif_ao_out";
							function = "spdif_ao_out";
							drive-strength-microamp = < 0x1f4 >;
							bias-disable;
						};
					};

					tdm-ao-b-din1 {

						mux {
							groups = "tdm_ao_b_din1";
							function = "tdm_ao_b";
							bias-disable;
						};
					};

					tdm-ao-b-din2 {

						mux {
							groups = "tdm_ao_b_din2";
							function = "tdm_ao_b";
							bias-disable;
						};
					};

					tdm-ao-b-dout0 {

						mux {
							groups = "tdm_ao_b_dout0";
							function = "tdm_ao_b";
							bias-disable;
							drive-strength-microamp = < 0xbb8 >;
						};
					};

					tdm-ao-b-dout1 {

						mux {
							groups = "tdm_ao_b_dout1";
							function = "tdm_ao_b";
							bias-disable;
							drive-strength-microamp = < 0xbb8 >;
						};
					};

					tdm-ao-b-dout2 {

						mux {
							groups = "tdm_ao_b_dout2";
							function = "tdm_ao_b";
							bias-disable;
							drive-strength-microamp = < 0xbb8 >;
						};
					};

					tdm-ao-b-fs {

						mux {
							groups = "tdm_ao_b_fs";
							function = "tdm_ao_b";
							bias-disable;
							drive-strength-microamp = < 0xbb8 >;
						};
					};

					tdm-ao-b-sclk {

						mux {
							groups = "tdm_ao_b_sclk";
							function = "tdm_ao_b";
							bias-disable;
							drive-strength-microamp = < 0xbb8 >;
						};
					};

					tdm-ao-b-slv-fs {

						mux {
							groups = "tdm_ao_b_slv_fs";
							function = "tdm_ao_b";
							bias-disable;
						};
					};

					tdm-ao-b-slv-sclk {

						mux {
							groups = "tdm_ao_b_slv_sclk";
							function = "tdm_ao_b";
							bias-disable;
						};
					};

					uart-a-ao {
						phandle = < 0x2c >;

						mux {
							groups = "uart_ao_a_tx\0uart_ao_a_rx";
							function = "uart_ao_a";
							bias-disable;
						};
					};

					uart-ao-a-cts-rts {

						mux {
							groups = "uart_ao_a_cts\0uart_ao_a_rts";
							function = "uart_ao_a";
							bias-disable;
						};
					};

					pwm-a-e {
						phandle = < 0x35 >;

						mux {
							groups = "pwm_a_e";
							function = "pwm_a_e";
							bias-disable;
						};
					};

					pwm-ao-a {

						mux {
							groups = "pwm_ao_a";
							function = "pwm_ao_a";
							bias-disable;
						};
					};

					pwm-ao-b {

						mux {
							groups = "pwm_ao_b";
							function = "pwm_ao_b";
							bias-disable;
						};
					};

					pwm-ao-c-4 {

						mux {
							groups = "pwm_ao_c_4";
							function = "pwm_ao_c";
							bias-disable;
						};
					};

					pwm-ao-c-6 {

						mux {
							groups = "pwm_ao_c_6";
							function = "pwm_ao_c";
							bias-disable;
						};
					};

					pwm-ao-d-5 {

						mux {
							groups = "pwm_ao_d_5";
							function = "pwm_ao_d";
							bias-disable;
						};
					};

					pwm-ao-d-10 {

						mux {
							groups = "pwm_ao_d_10";
							function = "pwm_ao_d";
							bias-disable;
						};
					};

					pwm-ao-d-e {
						phandle = < 0x2b >;

						mux {
							groups = "pwm_ao_d_e";
							function = "pwm_ao_d";
						};
					};

					remote-input-ao {
						phandle = < 0x30 >;

						mux {
							groups = "remote_ao_input";
							function = "remote_ao_input";
							bias-disable;
						};
					};
				};
			};

			rtc@0a8 {
				compatible = "amlogic,meson-vrtc";
				reg = < 0x00 0xa8 0x00 0x04 >;
			};

			cec@100 {
				compatible = "amlogic,meson-gx-ao-cec";
				reg = < 0x00 0x100 0x00 0x14 >;
				interrupts = < 0x00 0xc7 0x01 >;
				clocks = < 0x27 0x1b >;
				clock-names = "core";
				status = "disabled";
				pinctrl-0 = < 0x28 >;
				pinctrl-names = "default";
				hdmi-phandle = < 0x29 >;
			};

			ao-secure@140 {
				compatible = "amlogic,meson-gx-ao-secure\0syscon";
				reg = < 0x00 0x140 0x00 0x140 >;
				amlogic,has-chip-id;
				phandle = < 0x1d >;
			};

			cec@280 {
				compatible = "amlogic,meson-g12a-ao-cec";
				reg = < 0x00 0x280 0x00 0x1c >;
				interrupts = < 0x00 0xcb 0x01 >;
				clocks = < 0x27 0x13 >;
				clock-names = "oscin";
				status = "okay";
				pinctrl-0 = < 0x2a >;
				pinctrl-names = "default";
				hdmi-phandle = < 0x29 >;
			};

			pwm@2000 {
				compatible = "amlogic,meson-g12a-ao-pwm-cd";
				reg = < 0x00 0x2000 0x00 0x20 >;
				#pwm-cells = < 0x03 >;
				status = "okay";
				pinctrl-0 = < 0x2b >;
				pinctrl-names = "default";
				clocks = < 0x1e >;
				clock-names = "clkin1";
				phandle = < 0x57 >;
			};

			serial@3000 {
				compatible = "amlogic,meson-gx-uart\0amlogic,meson-ao-uart";
				reg = < 0x00 0x3000 0x00 0x18 >;
				interrupts = < 0x00 0xc1 0x01 >;
				clocks = < 0x1e 0x27 0x04 0x1e >;
				clock-names = "xtal\0pclk\0baud";
				status = "okay";
				pinctrl-0 = < 0x2c >;
				pinctrl-names = "default";
			};

			serial@4000 {
				compatible = "amlogic,meson-gx-uart\0amlogic,meson-ao-uart";
				reg = < 0x00 0x4000 0x00 0x18 >;
				interrupts = < 0x00 0xc5 0x01 >;
				clocks = < 0x1e 0x27 0x06 0x1e >;
				clock-names = "xtal\0pclk\0baud";
				status = "disabled";
			};

			i2c@5000 {
				compatible = "amlogic,meson-axg-i2c";
				status = "okay";
				reg = < 0x00 0x5000 0x00 0x20 >;
				interrupts = < 0x00 0xc3 0x01 >;
				#address-cells = < 0x01 >;
				#size-cells = < 0x00 >;
				clocks = < 0x02 0x18 >;
				pinctrl-0 = < 0x2d 0x2e >;
				pinctrl-names = "default";

				gpio-controller@20 {
					compatible = "ti,tca6408";
					reg = < 0x20 >;
					vcc-supply = < 0x2f >;
					gpio-controller;
					#gpio-cells = < 0x02 >;
					phandle = < 0x4d >;
				};

				rtc@51 {
					compatible = "haoyu,hym8563";
					reg = < 0x51 >;
					#clock-cells = < 0x00 >;
				};

				khadas-mcu@18 {
					status = "okay";
					compatible = "khadas-mcu";
					reg = < 0x18 >;
					fan,trig_temp_level0 = < 0x32 >;
					fan,trig_temp_level1 = < 0x3c >;
					fan,trig_temp_level2 = < 0x46 >;
					hwver = "VIM3.V11";
				};
			};

			pwm@7000 {
				compatible = "amlogic,meson-g12a-ao-pwm-ab";
				reg = < 0x00 0x7000 0x00 0x20 >;
				#pwm-cells = < 0x03 >;
				status = "disabled";
			};

			ir@8000 {
				compatible = "amlogic,meson-gxbb-ir";
				reg = < 0x00 0x8000 0x00 0x20 >;
				interrupts = < 0x00 0xc4 0x01 >;
				status = "okay";
				pinctrl-0 = < 0x30 >;
				pinctrl-names = "default";
				linux,rc-map-name = "rc-khadas";
			};

			adc@9000 {
				compatible = "amlogic,meson-g12a-saradc\0amlogic,meson-saradc";
				reg = < 0x00 0x9000 0x00 0x48 >;
				#io-channel-cells = < 0x01 >;
				interrupts = < 0x00 0xc8 0x01 >;
				clocks = < 0x1e 0x27 0x08 0x27 0x12 0x27 0x10 >;
				clock-names = "clkin\0core\0adc_clk\0adc_sel";
				status = "okay";
				vref-supply = < 0x31 >;
				phandle = < 0x4b >;
			};
		};

		video-decoder@ff620000 {
			compatible = "amlogic,g12a-vdec";
			reg = < 0x00 0xff620000 0x00 0x10000 0x00 0xffd0e180 0x00 0xe4 >;
			reg-names = "dos\0esparser";
			interrupts = < 0x00 0x2c 0x01 0x00 0x20 0x01 >;
			interrupt-names = "vdec\0esparser";
			amlogic,ao-sysctrl = < 0x21 >;
			amlogic,canvas = < 0x32 >;
			clocks = < 0x02 0x2e 0x02 0x10 0x02 0xcc 0x02 0xcf 0x02 0xd2 >;
			clock-names = "dos_parser\0dos\0vdec_1\0vdec_hevc\0vdec_hevcf";
			resets = < 0x05 0x28 >;
			reset-names = "esparser";
		};

		vpu@ff900000 {
			compatible = "amlogic,meson-g12a-vpu";
			reg = < 0x00 0xff900000 0x00 0x100000 0x00 0xff63c000 0x00 0x1000 >;
			reg-names = "vpu\0hhi";
			interrupts = < 0x00 0x03 0x01 >;
			#address-cells = < 0x01 >;
			#size-cells = < 0x00 >;
			amlogic,canvas = < 0x32 >;
			power-domains = < 0x03 0x00 >;

			port@0 {
				reg = < 0x00 >;
			};

			port@1 {
				reg = < 0x01 >;

				endpoint {
					remote-endpoint = < 0x33 >;
					phandle = < 0x1a >;
				};
			};
		};

		interrupt-controller@ffc01000 {
			compatible = "arm,gic-400";
			reg = < 0x00 0xffc01000 0x00 0x1000 0x00 0xffc02000 0x00 0x2000 0x00 0xffc04000 0x00 0x2000 0x00 0xffc06000 0x00 0x2000 >;
			interrupt-controller;
			interrupts = < 0x01 0x09 0xff04 >;
			#interrupt-cells = < 0x03 >;
			#address-cells = < 0x00 >;
			phandle = < 0x01 >;
		};

		bus@ffd00000 {
			compatible = "simple-bus";
			reg = < 0x00 0xffd00000 0x00 0x100000 >;
			#address-cells = < 0x02 >;
			#size-cells = < 0x02 >;
			ranges = < 0x00 0x00 0x00 0xffd00000 0x00 0x100000 >;

			reset-controller@1004 {
				compatible = "amlogic,meson-axg-reset";
				reg = < 0x00 0x1004 0x00 0x9c >;
				#reset-cells = < 0x01 >;
				phandle = < 0x05 >;
			};

			interrupt-controller@f080 {
				compatible = "amlogic,meson-g12a-gpio-intc\0amlogic,meson-gpio-intc";
				reg = < 0x00 0xf080 0x00 0x10 >;
				interrupt-controller;
				#interrupt-cells = < 0x02 >;
				amlogic,channel-interrupts = < 0x40 0x41 0x42 0x43 0x44 0x45 0x46 0x47 >;
				phandle = < 0x23 >;
			};

			pwm@19000 {
				compatible = "amlogic,meson-g12a-ee-pwm";
				reg = < 0x00 0x19000 0x00 0x20 >;
				#pwm-cells = < 0x03 >;
				status = "okay";
				pinctrl-0 = < 0x34 >;
				pinctrl-names = "default";
				phandle = < 0x55 >;
			};

			pwm@1a000 {
				compatible = "amlogic,meson-g12a-ee-pwm";
				reg = < 0x00 0x1a000 0x00 0x20 >;
				#pwm-cells = < 0x03 >;
				status = "disabled";
			};

			pwm@1b000 {
				compatible = "amlogic,meson-g12a-ee-pwm";
				reg = < 0x00 0x1b000 0x00 0x20 >;
				#pwm-cells = < 0x03 >;
				status = "okay";
				pinctrl-0 = < 0x35 >;
				pinctrl-names = "default";
				clocks = < 0x1e >;
				clock-names = "clkin0";
				phandle = < 0x56 >;
			};

			i2c@1c000 {
				compatible = "amlogic,meson-axg-i2c";
				status = "disabled";
				reg = < 0x00 0x1c000 0x00 0x20 >;
				interrupts = < 0x00 0x27 0x01 >;
				#address-cells = < 0x01 >;
				#size-cells = < 0x00 >;
				clocks = < 0x02 0x18 >;
			};

			i2c@1d000 {
				compatible = "amlogic,meson-axg-i2c";
				status = "disabled";
				reg = < 0x00 0x1d000 0x00 0x20 >;
				interrupts = < 0x00 0xd7 0x01 >;
				#address-cells = < 0x01 >;
				#size-cells = < 0x00 >;
				clocks = < 0x02 0x18 >;
			};

			i2c@1e000 {
				compatible = "amlogic,meson-axg-i2c";
				status = "disabled";
				reg = < 0x00 0x1e000 0x00 0x20 >;
				interrupts = < 0x00 0xd6 0x01 >;
				#address-cells = < 0x01 >;
				#size-cells = < 0x00 >;
				clocks = < 0x02 0x18 >;
			};

			i2c@1f000 {
				compatible = "amlogic,meson-axg-i2c";
				status = "disabled";
				reg = < 0x00 0x1f000 0x00 0x20 >;
				interrupts = < 0x00 0x15 0x01 >;
				#address-cells = < 0x01 >;
				#size-cells = < 0x00 >;
				clocks = < 0x02 0x18 >;
			};

			clock-measure@18000 {
				compatible = "amlogic,meson-g12a-clk-measure";
				reg = < 0x00 0x18000 0x00 0x10 >;
			};

			serial@22000 {
				compatible = "amlogic,meson-gx-uart";
				reg = < 0x00 0x22000 0x00 0x18 >;
				interrupts = < 0x00 0x5d 0x01 >;
				clocks = < 0x1e 0x02 0x39 0x1e >;
				clock-names = "xtal\0pclk\0baud";
				status = "disabled";
			};

			serial@23000 {
				compatible = "amlogic,meson-gx-uart";
				reg = < 0x00 0x23000 0x00 0x18 >;
				interrupts = < 0x00 0x4b 0x01 >;
				clocks = < 0x1e 0x02 0x2a 0x1e >;
				clock-names = "xtal\0pclk\0baud";
				status = "disabled";
			};

			serial@24000 {
				compatible = "amlogic,meson-gx-uart";
				reg = < 0x00 0x24000 0x00 0x18 >;
				interrupts = < 0x00 0x1a 0x01 >;
				clocks = < 0x1e 0x02 0x1c 0x1e >;
				clock-names = "xtal\0pclk\0baud";
				status = "okay";
				pinctrl-0 = < 0x36 0x37 >;
				pinctrl-names = "default";
				uart-has-rtscts;

				bluetooth {
					compatible = "brcm,bcm43438-bt";
					shutdown-gpios = < 0x07 0x52 0x00 >;
					max-speed = < 0x1e8480 >;
					clocks = < 0x38 >;
					clock-names = "lpo";
				};
			};
		};

		sd@ffe03000 {
			compatible = "amlogic,meson-axg-mmc";
			reg = < 0x00 0xffe03000 0x00 0x800 >;
			interrupts = < 0x00 0xbd 0x01 >;
			status = "okay";
			clocks = < 0x02 0x21 0x02 0x3c 0x02 0x02 >;
			clock-names = "core\0clkin0\0clkin1";
			resets = < 0x05 0x2c >;
			amlogic,dram-access-quirk;
			pinctrl-0 = < 0x39 >;
			pinctrl-1 = < 0x3a >;
			pinctrl-names = "default\0clk-gate";
			#address-cells = < 0x01 >;
			#size-cells = < 0x00 >;
			bus-width = < 0x04 >;
			cap-sd-highspeed;
			max-frequency = < 0x5f5e100 >;
			non-removable;
			disable-wp;
			keep-power-in-suspend;
			mmc-pwrseq = < 0x3b >;
			vmmc-supply = < 0x3c >;
			vqmmc-supply = < 0x31 >;

			wifi@1 {
				reg = < 0x01 >;
				compatible = "brcm,bcm4329-fmac";
			};
		};

		sd@ffe05000 {
			compatible = "amlogic,meson-axg-mmc";
			reg = < 0x00 0xffe05000 0x00 0x800 >;
			interrupts = < 0x00 0xbe 0x01 >;
			status = "okay";
			clocks = < 0x02 0x22 0x02 0x3d 0x02 0x02 >;
			clock-names = "core\0clkin0\0clkin1";
			resets = < 0x05 0x2d >;
			pinctrl-0 = < 0x3d >;
			pinctrl-1 = < 0x3e >;
			pinctrl-names = "default\0clk-gate";
			bus-width = < 0x04 >;
			cap-sd-highspeed;
			max-frequency = < 0x2faf080 >;
			disable-wp;
			cd-gpios = < 0x07 0x2f 0x01 >;
			vmmc-supply = < 0x3c >;
			vqmmc-supply = < 0x3c >;
		};

		mmc@ffe07000 {
			compatible = "amlogic,meson-axg-mmc";
			reg = < 0x00 0xffe07000 0x00 0x800 >;
			interrupts = < 0x00 0xbf 0x01 >;
			status = "okay";
			clocks = < 0x02 0x23 0x02 0x3e 0x02 0x02 >;
			clock-names = "core\0clkin0\0clkin1";
			resets = < 0x05 0x2e >;
			pinctrl-0 = < 0x3f 0x40 >;
			pinctrl-1 = < 0x41 >;
			pinctrl-names = "default\0clk-gate";
			bus-width = < 0x08 >;
			cap-mmc-highspeed;
			mmc-ddr-1_8v;
			mmc-hs200-1_8v;
			max-frequency = < 0xbebc200 >;
			disable-wp;
			mmc-pwrseq = < 0x42 >;
			vmmc-supply = < 0x2f >;
			vqmmc-supply = < 0x43 >;
		};

		usb@ffe09000 {
			status = "okay";
			compatible = "amlogic,meson-g12a-usb-ctrl";
			reg = < 0x00 0xffe09000 0x00 0xa0 >;
			interrupts = < 0x00 0x10 0x04 >;
			#address-cells = < 0x02 >;
			#size-cells = < 0x02 >;
			ranges;
			clocks = < 0x02 0x2f >;
			resets = < 0x05 0x22 >;
			dr_mode = "peripheral";
			phys = < 0x44 0x45 0x06 0x04 >;
			phy-names = "usb2-phy0\0usb2-phy1\0usb3-phy0";

			usb@ff400000 {
				compatible = "amlogic,meson-g12a-usb\0snps,dwc2";
				reg = < 0x00 0xff400000 0x00 0x40000 >;
				interrupts = < 0x00 0x1f 0x04 >;
				clocks = < 0x02 0x37 >;
				clock-names = "ddr";
				phys = < 0x45 >;
				phy-names = "usb2-phy";
				dr_mode = "peripheral";
				g-rx-fifo-size = < 0xc0 >;
				g-np-tx-fifo-size = < 0x80 >;
				g-tx-fifo-size = < 0x80 0x80 0x10 0x10 0x10 >;
			};

			usb@ff500000 {
				compatible = "snps,dwc3";
				reg = < 0x00 0xff500000 0x00 0x100000 >;
				interrupts = < 0x00 0x1e 0x04 >;
				dr_mode = "host";
				snps,dis_u2_susphy_quirk;
				snps,quirk-frame-length-adjustment;
				snps,parkmode-disable-ss-quirk;
			};
		};

		gpu@ffe40000 {
			compatible = "amlogic,meson-g12a-mali\0arm,mali-bifrost";
			reg = < 0x00 0xffe40000 0x00 0x40000 >;
			interrupt-parent = < 0x01 >;
			interrupts = < 0x00 0xa2 0x04 0x00 0xa1 0x04 0x00 0xa0 0x04 >;
			interrupt-names = "job\0mmu\0gpu";
			clocks = < 0x02 0xaf >;
			resets = < 0x05 0x14 0x05 0x4e >;
			assigned-clocks = < 0x02 0xa9 0x02 0xab 0x02 0xaf >;
			assigned-clock-parents = < 0x02 0x63 0x00 0x02 0xab >;
			assigned-clock-rates = < 0x00 0x2faf0800 0x00 >;
			#cooling-cells = < 0x02 >;
			phandle = < 0x13 >;
		};
	};

	timer {
		compatible = "arm,armv8-timer";
		interrupts = < 0x01 0x0d 0xff08 0x01 0x0e 0xff08 0x01 0x0b 0xff08 0x01 0x0a 0xff08 >;
		arm,no-tick-in-suspend;
	};

	xtal-clk {
		compatible = "fixed-clock";
		clock-frequency = < 0x16e3600 >;
		clock-output-names = "xtal";
		#clock-cells = < 0x00 >;
		phandle = < 0x1e >;
	};

	audio-controller-0 {
		compatible = "amlogic,axg-tdm-iface";
		#sound-dai-cells = < 0x00 >;
		sound-name-prefix = "TDM_A";
		clocks = < 0x24 0x31 0x24 0x4f 0x24 0x56 >;
		clock-names = "mclk\0sclk\0lrclk";
		status = "disabled";
	};

	audio-controller-1 {
		compatible = "amlogic,axg-tdm-iface";
		#sound-dai-cells = < 0x00 >;
		sound-name-prefix = "TDM_B";
		clocks = < 0x24 0x32 0x24 0x50 0x24 0x57 >;
		clock-names = "mclk\0sclk\0lrclk";
		status = "okay";
		phandle = < 0x52 >;
	};

	audio-controller-2 {
		compatible = "amlogic,axg-tdm-iface";
		#sound-dai-cells = < 0x00 >;
		sound-name-prefix = "TDM_C";
		clocks = < 0x24 0x33 0x24 0x51 0x24 0x58 >;
		clock-names = "mclk\0sclk\0lrclk";
		status = "disabled";
	};

	cpus {
		#address-cells = < 0x02 >;
		#size-cells = < 0x00 >;

		cpu-map {

			cluster0 {

				core0 {
					cpu = < 0x0a >;
				};

				core1 {
					cpu = < 0x0b >;
				};
			};

			cluster1 {

				core0 {
					cpu = < 0x0c >;
				};

				core1 {
					cpu = < 0x0d >;
				};

				core2 {
					cpu = < 0x0e >;
				};

				core3 {
					cpu = < 0x0f >;
				};
			};
		};

		cpu@0 {
			device_type = "cpu";
			compatible = "arm,cortex-a53";
			reg = < 0x00 0x00 >;
			enable-method = "psci";
			capacity-dmips-mhz = < 0x250 >;
			next-level-cache = < 0x46 >;
			#cooling-cells = < 0x02 >;
			cpu-supply = < 0x47 >;
			operating-points-v2 = < 0x48 >;
			clocks = < 0x02 0xbb >;
			clock-latency = < 0xc350 >;
			phandle = < 0x0a >;
		};

		cpu@1 {
			device_type = "cpu";
			compatible = "arm,cortex-a53";
			reg = < 0x00 0x01 >;
			enable-method = "psci";
			capacity-dmips-mhz = < 0x250 >;
			next-level-cache = < 0x46 >;
			#cooling-cells = < 0x02 >;
			cpu-supply = < 0x47 >;
			operating-points-v2 = < 0x48 >;
			clocks = < 0x02 0xbb >;
			clock-latency = < 0xc350 >;
			phandle = < 0x0b >;
		};

		cpu@100 {
			device_type = "cpu";
			compatible = "arm,cortex-a73";
			reg = < 0x00 0x100 >;
			enable-method = "psci";
			capacity-dmips-mhz = < 0x400 >;
			next-level-cache = < 0x46 >;
			#cooling-cells = < 0x02 >;
			cpu-supply = < 0x49 >;
			operating-points-v2 = < 0x4a >;
			clocks = < 0x02 0xe0 >;
			clock-latency = < 0xc350 >;
			phandle = < 0x0c >;
		};

		cpu@101 {
			device_type = "cpu";
			compatible = "arm,cortex-a73";
			reg = < 0x00 0x101 >;
			enable-method = "psci";
			capacity-dmips-mhz = < 0x400 >;
			next-level-cache = < 0x46 >;
			#cooling-cells = < 0x02 >;
			cpu-supply = < 0x49 >;
			operating-points-v2 = < 0x4a >;
			clocks = < 0x02 0xe0 >;
			clock-latency = < 0xc350 >;
			phandle = < 0x0d >;
		};

		cpu@102 {
			device_type = "cpu";
			compatible = "arm,cortex-a73";
			reg = < 0x00 0x102 >;
			enable-method = "psci";
			capacity-dmips-mhz = < 0x400 >;
			next-level-cache = < 0x46 >;
			#cooling-cells = < 0x02 >;
			cpu-supply = < 0x49 >;
			operating-points-v2 = < 0x4a >;
			clocks = < 0x02 0xe0 >;
			clock-latency = < 0xc350 >;
			phandle = < 0x0e >;
		};

		cpu@103 {
			device_type = "cpu";
			compatible = "arm,cortex-a73";
			reg = < 0x00 0x103 >;
			enable-method = "psci";
			capacity-dmips-mhz = < 0x400 >;
			next-level-cache = < 0x46 >;
			#cooling-cells = < 0x02 >;
			cpu-supply = < 0x49 >;
			operating-points-v2 = < 0x4a >;
			clocks = < 0x02 0xe0 >;
			clock-latency = < 0xc350 >;
			phandle = < 0x0f >;
		};

		l2-cache0 {
			compatible = "cache";
			phandle = < 0x46 >;
		};
	};

	opp-table-0 {
		compatible = "operating-points-v2";
		opp-shared;
		phandle = < 0x48 >;

		opp-100000000 {
			opp-hz = < 0x00 0x5f5e100 >;
			opp-microvolt = < 0xb2778 >;
		};

		opp-250000000 {
			opp-hz = < 0x00 0xee6b280 >;
			opp-microvolt = < 0xb2778 >;
		};

		opp-500000000 {
			opp-hz = < 0x00 0x1dcd6500 >;
			opp-microvolt = < 0xb2778 >;
		};

		opp-667000000 {
			opp-hz = < 0x00 0x27c19cc0 >;
			opp-microvolt = < 0xb2778 >;
		};

		opp-1000000000 {
			opp-hz = < 0x00 0x3b9aca00 >;
			opp-microvolt = < 0xb9ca8 >;
		};

		opp-1200000000 {
			opp-hz = < 0x00 0x47868c00 >;
			opp-microvolt = < 0xbeac8 >;
		};

		opp-1398000000 {
			opp-hz = < 0x00 0x5353c980 >;
			opp-microvolt = < 0xc5ff8 >;
		};

		opp-1512000000 {
			opp-hz = < 0x00 0x5a1f4a00 >;
			opp-microvolt = < 0xd2348 >;
		};

		opp-1608000000 {
			opp-hz = < 0x00 0x5fd82200 >;
			opp-microvolt = < 0xdbf88 >;
		};

		opp-1704000000 {
			opp-hz = < 0x00 0x6590fa00 >;
			opp-microvolt = < 0xe82d8 >;
		};

		opp-1800000000 {
			opp-hz = < 0x00 0x6b49d200 >;
			opp-microvolt = < 0xf4628 >;
		};
	};

	opp-table-1 {
		compatible = "operating-points-v2";
		opp-shared;
		phandle = < 0x4a >;

		opp-100000000 {
			opp-hz = < 0x00 0x5f5e100 >;
			opp-microvolt = < 0xb2778 >;
		};

		opp-250000000 {
			opp-hz = < 0x00 0xee6b280 >;
			opp-microvolt = < 0xb2778 >;
		};

		opp-500000000 {
			opp-hz = < 0x00 0x1dcd6500 >;
			opp-microvolt = < 0xb2778 >;
		};

		opp-667000000 {
			opp-hz = < 0x00 0x27c19cc0 >;
			opp-microvolt = < 0xb2778 >;
		};

		opp-1000000000 {
			opp-hz = < 0x00 0x3b9aca00 >;
			opp-microvolt = < 0xb2778 >;
		};

		opp-1200000000 {
			opp-hz = < 0x00 0x47868c00 >;
			opp-microvolt = < 0xb7598 >;
		};

		opp-1398000000 {
			opp-hz = < 0x00 0x5353c980 >;
			opp-microvolt = < 0xbc3b8 >;
		};

		opp-1512000000 {
			opp-hz = < 0x00 0x5a1f4a00 >;
			opp-microvolt = < 0xbc3b8 >;
		};

		opp-1608000000 {
			opp-hz = < 0x00 0x5fd82200 >;
			opp-microvolt = < 0xbeac8 >;
		};

		opp-1704000000 {
			opp-hz = < 0x00 0x6590fa00 >;
			opp-microvolt = < 0xc11d8 >;
		};

		opp-1800000000 {
			opp-hz = < 0x00 0x6b49d200 >;
			opp-microvolt = < 0xcae18 >;
		};

		opp-1908000000 {
			opp-hz = < 0x00 0x71b9c500 >;
			opp-microvolt = < 0xd2348 >;
		};

		opp-2016000000 {
			opp-hz = < 0x00 0x7829b800 >;
			opp-microvolt = < 0xde698 >;
		};

		opp-2108000000 {
			opp-hz = < 0x00 0x7da58700 >;
			opp-microvolt = < 0xe82d8 >;
		};

		opp-2208000000 {
			opp-hz = < 0x00 0x839b6800 >;
			opp-microvolt = < 0xf6d38 >;
		};
	};

	aliases {
		serial0 = "/soc/bus@ff800000/serial@3000";
		ethernet0 = "/soc/ethernet@ff3f0000";
	};

	memory@0 {
		device_type = "memory";
		reg = < 0x00 0x00 0x00 0x80000000 >;
	};

	adc-keys {
		compatible = "adc-keys";
		io-channels = < 0x4b 0x02 >;
		io-channel-names = "buttons";
		keyup-threshold-microvolt = < 0x1a17b0 >;

		button-function {
			label = "Function";
			linux,code = < 0x1d0 >;
			press-threshold-microvolt = < 0x2710 >;
		};
	};

	leds {
		compatible = "gpio-leds";

		white {
			label = "vim3:white:sys";
			gpios = < 0x4c 0x04 0x01 >;
		};

		red {
			label = "vim3:red";
			gpios = < 0x4d 0x05 0x01 >;
		};
	};

	emmc-pwrseq {
		compatible = "mmc-pwrseq-emmc";
		reset-gpios = < 0x07 0x25 0x01 >;
		phandle = < 0x42 >;
	};

	gpio-keys-polled {
		compatible = "gpio-keys-polled";
		poll-interval = < 0x64 >;

		power-button {
			label = "power";
			linux,code = < 0x74 >;
			gpios = < 0x4c 0x07 0x01 >;
		};
	};

	sdio-pwrseq {
		compatible = "mmc-pwrseq-simple";
		reset-gpios = < 0x07 0x47 0x01 >;
		clocks = < 0x38 >;
		clock-names = "ext_clock";
		phandle = < 0x3b >;
	};

	sound {
		compatible = "amlogic,axg-sound-card";
		model = "G12A-KHADAS-VIM3";
		audio-aux-devs = < 0x4e >;
		audio-routing = "TDMOUT_B IN 0\0FRDDR_A OUT 1\0TDMOUT_B IN 1\0FRDDR_B OUT 1\0TDMOUT_B IN 2\0FRDDR_C OUT 1\0TDM_B Playback\0TDMOUT_B OUT";
		assigned-clocks = < 0x02 0x0d 0x02 0x0b 0x02 0x0c >;
		assigned-clock-parents = < 0x00 0x00 0x00 >;
		assigned-clock-rates = < 0x11940000 0x10266000 0x17700000 >;
		status = "okay";

		dai-link-0 {
			sound-dai = < 0x4f >;
		};

		dai-link-1 {
			sound-dai = < 0x50 >;
		};

		dai-link-2 {
			sound-dai = < 0x51 >;
		};

		dai-link-3 {
			sound-dai = < 0x52 >;
			dai-format = "i2s";
			dai-tdm-slot-tx-mask-0 = < 0x01 0x01 >;
			dai-tdm-slot-tx-mask-1 = < 0x01 0x01 >;
			dai-tdm-slot-tx-mask-2 = < 0x01 0x01 >;
			dai-tdm-slot-tx-mask-3 = < 0x01 0x01 >;
			mclk-fs = < 0x100 >;

			codec {
				sound-dai = < 0x53 0x01 >;
			};
		};

		dai-link-4 {
			sound-dai = < 0x53 0x03 >;

			codec {
				sound-dai = < 0x29 >;
			};
		};
	};

	regulator-dc_in {
		compatible = "regulator-fixed";
		regulator-name = "DC_IN";
		regulator-min-microvolt = < 0x4c4b40 >;
		regulator-max-microvolt = < 0x4c4b40 >;
		regulator-always-on;
		phandle = < 0x1f >;
	};

	regulator-vcc_5v {
		compatible = "regulator-fixed";
		regulator-name = "VCC_5V";
		regulator-min-microvolt = < 0x4c4b40 >;
		regulator-max-microvolt = < 0x4c4b40 >;
		vin-supply = < 0x1f >;
		gpio = < 0x07 0x18 0x06 >;
		enable-active-high;
		phandle = < 0x19 >;
	};

	regulator-vcc_1v8 {
		compatible = "regulator-fixed";
		regulator-name = "VCC_1V8";
		regulator-min-microvolt = < 0x1b7740 >;
		regulator-max-microvolt = < 0x1b7740 >;
		vin-supply = < 0x2f >;
		regulator-always-on;
	};

	regulator-vcc_3v3 {
		compatible = "regulator-fixed";
		regulator-name = "VCC_3V3";
		regulator-min-microvolt = < 0x325aa0 >;
		regulator-max-microvolt = < 0x325aa0 >;
		vin-supply = < 0x3c >;
		regulator-always-on;
		phandle = < 0x2f >;
	};

	regulator-vddao_1v8 {
		compatible = "regulator-fixed";
		regulator-name = "VDDIO_AO1V8";
		regulator-min-microvolt = < 0x1b7740 >;
		regulator-max-microvolt = < 0x1b7740 >;
		vin-supply = < 0x3c >;
		regulator-always-on;
		phandle = < 0x31 >;
	};

	regulator-emmc_1v8 {
		compatible = "regulator-fixed";
		regulator-name = "EMMC_AO1V8";
		regulator-min-microvolt = < 0x1b7740 >;
		regulator-max-microvolt = < 0x1b7740 >;
		vin-supply = < 0x2f >;
		regulator-always-on;
		phandle = < 0x43 >;
	};

	regulator-vsys_3v3 {
		compatible = "regulator-fixed";
		regulator-name = "VSYS_3V3";
		regulator-min-microvolt = < 0x325aa0 >;
		regulator-max-microvolt = < 0x325aa0 >;
		vin-supply = < 0x1f >;
		regulator-always-on;
		phandle = < 0x3c >;
	};

	regulator-usb_pwr {
		compatible = "regulator-fixed";
		regulator-name = "USB_PWR";
		regulator-min-microvolt = < 0x4c4b40 >;
		regulator-max-microvolt = < 0x4c4b40 >;
		vin-supply = < 0x19 >;
		gpio = < 0x07 0x37 0x00 >;
		enable-active-high;
		phandle = < 0x20 >;
	};

	hdmi-connector {
		compatible = "hdmi-connector";
		type = [ 61 00 ];

		port {

			endpoint {
				remote-endpoint = < 0x54 >;
				phandle = < 0x1b >;
			};
		};
	};

	wifi32k {
		compatible = "pwm-clock";
		#clock-cells = < 0x00 >;
		clock-frequency = < 0x8000 >;
		pwms = < 0x55 0x00 0x7736 0x00 >;
		phandle = < 0x38 >;
	};

	regulator-vddcpu-a {
		compatible = "pwm-regulator";
		regulator-name = "VDDCPU_A";
		regulator-min-microvolt = < 0xa8750 >;
		regulator-max-microvolt = < 0x100590 >;
		vin-supply = < 0x1f >;
		pwms = < 0x56 0x00 0x4e2 0x00 >;
		pwm-dutycycle-range = < 0x64 0x00 >;
		regulator-boot-on;
		regulator-always-on;
		phandle = < 0x49 >;
	};

	regulator-vddcpu-b {
		compatible = "pwm-regulator";
		regulator-name = "VDDCPU_B";
		regulator-min-microvolt = < 0xa8750 >;
		regulator-max-microvolt = < 0x100590 >;
		vin-supply = < 0x3c >;
		pwms = < 0x57 0x01 0x4e2 0x00 >;
		pwm-dutycycle-range = < 0x64 0x00 >;
		regulator-boot-on;
		regulator-always-on;
		phandle = < 0x47 >;
	};
};
